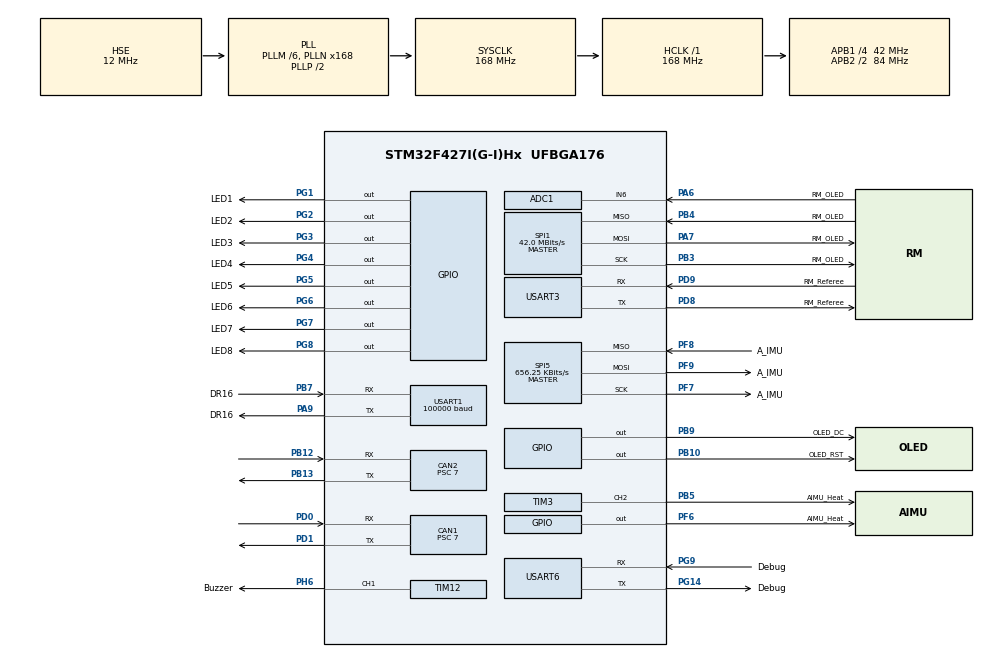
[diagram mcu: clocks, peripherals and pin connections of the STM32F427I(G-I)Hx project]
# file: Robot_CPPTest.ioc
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ADC1.Channel-0\#ChannelRegularConversion=ADC_CHANNEL_6
ADC1.NbrOfConversionFlag=1
ADC1.Rank-0\#ChannelRegularConversion=1
ADC1.SamplingTime-0\#ChannelRegularConversion=ADC_SAMPLETIME_15CYCLES
ADC1.master=1
CAN1.ABOM=ENABLE
CAN1.AWUM=ENABLE
CAN1.BS1=CAN_BS1_3TQ
CAN1.BS2=CAN_BS2_2TQ
CAN1.CalculateTimeQuantum=166.66666666666669
CAN1.NART=ENABLE
CAN1.Prescaler=7
CAN1.SJW=CAN_SJW_1TQ
CAN1.TXFP=ENABLE
CAN2.ABOM=ENABLE
CAN2.AWUM=ENABLE
CAN2.BS1=CAN_BS1_3TQ
CAN2.BS2=CAN_BS2_2TQ
CAN2.CalculateTimeQuantum=166.66666666666669
CAN2.NART=ENABLE
CAN2.Prescaler=7
CAN2.TXFP=ENABLE
Dma.Request0=USART1_RX
Dma.Request1=USART3_RX
Dma.Request2=USART3_TX
Dma.Request3=USART6_TX
Dma.USART1_RX.0.Direction=DMA_PERIPH_TO_MEMORY
Dma.USART1_RX.0.FIFOMode=DMA_FIFOMODE_DISABLE
Dma.USART1_RX.0.Instance=DMA2_Stream2
Dma.USART1_RX.0.MemDataAlignment=DMA_MDATAALIGN_BYTE
Dma.USART1_RX.0.MemInc=DMA_MINC_ENABLE
Dma.USART1_RX.0.Mode=DMA_CIRCULAR
Dma.USART1_RX.0.PeriphDataAlignment=DMA_PDATAALIGN_BYTE
Dma.USART1_RX.0.PeriphInc=DMA_PINC_DISABLE
Dma.USART1_RX.0.Priority=DMA_PRIORITY_LOW
Dma.USART3_RX.1.Direction=DMA_PERIPH_TO_MEMORY
Dma.USART3_RX.1.FIFOMode=DMA_FIFOMODE_DISABLE
Dma.USART3_RX.1.Instance=DMA1_Stream1
Dma.USART3_RX.1.MemDataAlignment=DMA_MDATAALIGN_BYTE
Dma.USART3_RX.1.MemInc=DMA_MINC_ENABLE
Dma.USART3_RX.1.Mode=DMA_CIRCULAR
Dma.USART3_RX.1.PeriphDataAlignment=DMA_PDATAALIGN_BYTE
Dma.USART3_RX.1.PeriphInc=DMA_PINC_DISABLE
Dma.USART3_RX.1.Priority=DMA_PRIORITY_LOW
Dma.USART3_TX.2.Direction=DMA_MEMORY_TO_PERIPH
Dma.USART3_TX.2.FIFOMode=DMA_FIFOMODE_DISABLE
Dma.USART3_TX.2.Instance=DMA1_Stream3
Dma.USART3_TX.2.MemDataAlignment=DMA_MDATAALIGN_BYTE
Dma.USART3_TX.2.MemInc=DMA_MINC_ENABLE
Dma.USART3_TX.2.Mode=DMA_NORMAL
Dma.USART3_TX.2.PeriphDataAlignment=DMA_PDATAALIGN_BYTE
Dma.USART3_TX.2.PeriphInc=DMA_PINC_DISABLE
Dma.USART3_TX.2.Priority=DMA_PRIORITY_LOW
Dma.USART6_TX.3.Direction=DMA_MEMORY_TO_PERIPH
Dma.USART6_TX.3.FIFOMode=DMA_FIFOMODE_DISABLE
Dma.USART6_TX.3.Instance=DMA2_Stream6
Dma.USART6_TX.3.MemDataAlignment=DMA_MDATAALIGN_BYTE
Dma.USART6_TX.3.MemInc=DMA_MINC_ENABLE
Dma.USART6_TX.3.Mode=DMA_NORMAL
Dma.USART6_TX.3.PeriphDataAlignment=DMA_PDATAALIGN_BYTE
Dma.USART6_TX.3.PeriphInc=DMA_PINC_DISABLE
Dma.USART6_TX.3.Priority=DMA_PRIORITY_LOW
FREERTOS.INCLUDE_vTaskDelayUntil=1
FREERTOS.Tasks01=Activate_Task,0,128,User_SystemInit_Task,Default,NULL,Dynamic,NULL,NULL
Mcu.Family=STM32F4
Mcu.Name=STM32F427I(G-I)Hx
Mcu.Package=UFBGA176
NVIC.CAN1_RX0_IRQn=true\:5\:0\:true\:false\:true\:false\:true\:true
NVIC.CAN2_RX0_IRQn=true\:5\:0\:true\:false\:true\:false\:true\:true
NVIC.DMA1_Stream1_IRQn=true\:5\:0\:true\:false\:true\:true\:false\:true
NVIC.DMA1_Stream3_IRQn=true\:5\:0\:true\:false\:true\:true\:false\:true
NVIC.DMA2_Stream2_IRQn=true\:0\:0\:false\:false\:true\:true\:false\:true
NVIC.DMA2_Stream6_IRQn=true\:5\:0\:true\:false\:true\:true\:false\:true
NVIC.PriorityGroup=NVIC_PRIORITYGROUP_4
NVIC.TIM6_DAC_IRQn=true\:0\:0\:false\:false\:true\:false\:false\:true
NVIC.TimeBase=TIM6_DAC_IRQn
NVIC.TimeBaseIP=TIM6
NVIC.USART1_IRQn=true\:5\:0\:true\:false\:true\:false\:true\:true
NVIC.USART3_IRQn=true\:5\:0\:true\:false\:true\:true\:true\:true
NVIC.USART6_IRQn=true\:5\:0\:true\:false\:true\:false\:true\:true
PA13.Mode=Serial_Wire
PA13.Signal=SYS_JTMS-SWDIO
PA14.Mode=Serial_Wire
PA14.Signal=SYS_JTCK-SWCLK
PA6.GPIO_Label=RM_OLED
PA6.Signal=ADCx_IN6
PA7.GPIO_Label=RM_OLED
PA7.Mode=Full_Duplex_Master
PA7.Signal=SPI1_MOSI
PA9.GPIO_Label=DR16
PA9.Mode=Asynchronous
PA9.Signal=USART1_TX
PB10.GPIO_Label=OLED_RST
PB10.Signal=GPIO_Output
PB12.Mode=Slave
PB12.Signal=CAN2_RX
PB13.Mode=Slave
PB13.Signal=CAN2_TX
PB3.GPIO_Label=RM_OLED
PB3.Mode=Full_Duplex_Master
PB3.Signal=SPI1_SCK
PB4.GPIO_Label=RM_OLED
PB4.Mode=Full_Duplex_Master
PB4.Signal=SPI1_MISO
PB5.GPIO_Label=AIMU_Heat
PB5.Signal=S_TIM3_CH2
PB7.GPIO_Label=DR16
PB7.Mode=Asynchronous
PB7.Signal=USART1_RX
PB9.GPIO_Label=OLED_DC
PB9.Signal=GPIO_Output
PD0.Mode=Master
PD0.Signal=CAN1_RX
PD1.Mode=Master
PD1.Signal=CAN1_TX
PD8.GPIO_Label=RM_Referee
PD8.Mode=Asynchronous
PD8.Signal=USART3_TX
PD9.GPIO_Label=RM_Referee
PD9.Mode=Asynchronous
PD9.Signal=USART3_RX
PF6.GPIO_Label=AIMU_Heat
PF6.PinState=GPIO_PIN_SET
PF6.Signal=GPIO_Output
PF7.GPIO_Label=A_IMU
PF7.Mode=Full_Duplex_Master
PF7.Signal=SPI5_SCK
PF8.GPIO_Label=A_IMU
PF8.Mode=Full_Duplex_Master
PF8.Signal=SPI5_MISO
PF9.GPIO_Label=A_IMU
PF9.Mode=Full_Duplex_Master
PF9.Signal=SPI5_MOSI
PG1.GPIO_Label=LED1
PG1.GPIO_PuPd=GPIO_PULLUP
PG1.PinState=GPIO_PIN_SET
PG1.Signal=GPIO_Output
PG14.GPIO_Label=Debug
PG14.Mode=Asynchronous
PG14.Signal=USART6_TX
PG2.GPIO_Label=LED2
PG2.GPIO_PuPd=GPIO_PULLUP
PG2.PinState=GPIO_PIN_SET
PG2.Signal=GPIO_Output
PG3.GPIO_Label=LED3
PG3.GPIO_PuPd=GPIO_PULLUP
PG3.PinState=GPIO_PIN_SET
PG3.Signal=GPIO_Output
PG4.GPIO_Label=LED4
PG4.GPIO_PuPd=GPIO_PULLUP
PG4.PinState=GPIO_PIN_SET
PG4.Signal=GPIO_Output
PG5.GPIO_Label=LED5
PG5.GPIO_PuPd=GPIO_PULLUP
PG5.PinState=GPIO_PIN_SET
PG5.Signal=GPIO_Output
PG6.GPIO_Label=LED6
PG6.GPIO_PuPd=GPIO_PULLUP
PG6.PinState=GPIO_PIN_SET
PG6.Signal=GPIO_Output
PG7.GPIO_Label=LED7
PG7.GPIO_ModeDefaultOutputPP=GPIO_MODE_OUTPUT_PP
PG7.GPIO_PuPd=GPIO_PULLUP
PG7.PinState=GPIO_PIN_SET
PG7.Signal=GPIO_Output
PG8.GPIO_Label=LED8
PG8.GPIO_PuPd=GPIO_PULLUP
PG8.PinState=GPIO_PIN_SET
PG8.Signal=GPIO_Output
PG9.GPIO_Label=Debug
PG9.Mode=Asynchronous
PG9.Signal=USART6_RX
PH0/OSC_IN.Mode=HSE-External-Oscillator
PH0/OSC_IN.Signal=RCC_OSC_IN
PH1/OSC_OUT.Mode=HSE-External-Oscillator
PH1/OSC_OUT.Signal=RCC_OSC_OUT
PH6.GPIO_Label=Buzzer
PH6.Signal=S_TIM12_CH1
ProjectManager.HeapSize=0x200
ProjectManager.StackSize=0x400
ProjectManager.TargetToolchain=MDK-ARM V5.27
RCC.48MHZClocksFreq_Value=84000000
RCC.AHBFreq_Value=168000000
RCC.APB1CLKDivider=RCC_HCLK_DIV4
RCC.APB1Freq_Value=42000000
RCC.APB1TimFreq_Value=84000000
RCC.APB2CLKDivider=RCC_HCLK_DIV2
RCC.APB2Freq_Value=84000000
RCC.APB2TimFreq_Value=168000000
RCC.CortexFreq_Value=168000000
RCC.HCLKFreq_Value=168000000
RCC.HSE_VALUE=12000000
RCC.HSI_VALUE=16000000
RCC.LSE_VALUE=32768
RCC.PLLM=6
RCC.PLLN=168
RCC.PLLSourceVirtual=RCC_PLLSOURCE_HSE
RCC.SYSCLKFreq_VALUE=168000000
RCC.SYSCLKSource=RCC_SYSCLKSOURCE_PLLCLK
RCC.VCOOutputFreq_Value=336000000
SH.ADCx_IN6.0=ADC1_IN6,IN6
SH.S_TIM12_CH1.0=TIM12_CH1,PWM Generation1 CH1
SH.S_TIM3_CH2.0=TIM3_CH2,PWM Generation2 CH2
SPI1.CalculateBaudRate=42.0 MBits/s
SPI1.Direction=SPI_DIRECTION_2LINES
SPI1.Mode=SPI_MODE_MASTER
SPI1.VirtualType=VM_MASTER
SPI5.BaudRatePrescaler=SPI_BAUDRATEPRESCALER_128
SPI5.CalculateBaudRate=656.25 KBits/s
SPI5.Direction=SPI_DIRECTION_2LINES
SPI5.Mode=SPI_MODE_MASTER
SPI5.VirtualType=VM_MASTER
TIM12.Channel-PWM\ Generation1\ CH1=TIM_CHANNEL_1
TIM12.Period=2499
TIM12.Prescaler=83
TIM12.Pulse-PWM\ Generation1\ CH1=1000
TIM3.Channel-PWM\ Generation2\ CH2=TIM_CHANNEL_2
TIM3.Period=4999
USART1.BaudRate=100000
USART1.Parity=PARITY_EVEN
USART1.VirtualMode=VM_ASYNC
USART1.WordLength=WORDLENGTH_9B
USART3.VirtualMode=VM_ASYNC
USART6.VirtualMode=VM_ASYNC
VP_FREERTOS_VS_CMSIS_V1.Mode=CMSIS_V1
VP_SYS_VS_tim6.Mode=TIM6
VP_TIM12_VS_ClockSourceINT.Mode=Internal
board=custom

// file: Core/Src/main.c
/* USER CODE BEGIN Header */
/**
  ******************************************************************************
  * @file           : main.c
  * @brief          : Main program body
  ******************************************************************************
  * @attention
  *
  * <h2><center>&copy; Copyright (c) 2021 STMicroelectronics.
  * All rights reserved.</center></h2>
  *
  * This software component is licensed by ST under Ultimate Liberty license
  * SLA0044, the "License"; You may not use this file except in compliance with
  * the License. You may obtain a copy of the License at:
  *                             www.st.com/SLA0044
  *
  ******************************************************************************
  */
/* USER CODE END Header */
#include "main.h"
#include "cmsis_os.h"
#include "adc.h"
#include "can.h"
#include "dma.h"
#include "spi.h"
#include "tim.h"
#include "usart.h"
#include "gpio.h"

/* USER CODE BEGIN Includes */
#include "System_Config.h"
#include "DJI_AIMU.h"//这里进行了修改test
#include "BSP_FLASH.h"
#include "BSP_FlashStore.h"
/* USER CODE END Includes */

void SystemClock_Config(void);
void MX_FREERTOS_Init(void);

int main(void)
{

  /* MCU Configuration--------------------------------------------------------*/

  HAL_Init();

  /* Configure the system clock */
  SystemClock_Config();

  /* Initialize all configured peripherals */
  MX_GPIO_Init();
  MX_DMA_Init();
  MX_CAN1_Init();
  MX_CAN2_Init();
  MX_USART1_UART_Init();
  MX_USART6_UART_Init();
  MX_SPI5_Init();
  MX_TIM3_Init();
  MX_USART3_UART_Init();
  MX_ADC1_Init();
  MX_SPI1_Init();
  MX_TIM12_Init();
  /* USER CODE BEGIN 2 */
#if AIMU_Calibrate == AIMU_Calibrate_Off
  flash_read(STM32_FLASH_BASE, IMU_Offset, 6);
#endif
  User_System_Init();

  /* USER CODE END 2 */

  /* Call init function for freertos objects (in freertos.c) */
  MX_FREERTOS_Init();
  /* Start scheduler */
  osKernelStart();

  /* We should never get here as control is now taken by the scheduler */
  /* Infinite loop */
  /* USER CODE BEGIN WHILE */
#if AIMU_Calibrate == AIMU_Calibrate_On
  flash_write_single_address(STM32_FLASH_BASE, IMUwriteFlashData, 6);
  // DJI_IMUWriteOffset(IMUwriteFlashData,6);
#endif
  while (1)
  {
    /* USER CODE END WHILE */

  }
}

void SystemClock_Config(void)
{
  RCC_OscInitTypeDef RCC_OscInitStruct = {0};
  RCC_ClkInitTypeDef RCC_ClkInitStruct = {0};

  /** Configure the main internal regulator output voltage
  */
  __HAL_RCC_PWR_CLK_ENABLE();
  __HAL_PWR_VOLTAGESCALING_CONFIG(PWR_REGULATOR_VOLTAGE_SCALE1);
  /** Initializes the RCC Oscillators according to the specified parameters
  * in the RCC_OscInitTypeDef structure.
  */
  RCC_OscInitStruct.OscillatorType = RCC_OSCILLATORTYPE_HSE;
  RCC_OscInitStruct.HSEState = RCC_HSE_ON;
  RCC_OscInitStruct.PLL.PLLState = RCC_PLL_ON;
  RCC_OscInitStruct.PLL.PLLSource = RCC_PLLSOURCE_HSE;
  RCC_OscInitStruct.PLL.PLLM = 6;
  RCC_OscInitStruct.PLL.PLLN = 168;
  RCC_OscInitStruct.PLL.PLLP = RCC_PLLP_DIV2;
  RCC_OscInitStruct.PLL.PLLQ = 4;
  if (HAL_RCC_OscConfig(&RCC_OscInitStruct) != HAL_OK)
  {
    Error_Handler();
  }
  /** Initializes the CPU, AHB and APB buses clocks
  */
  RCC_ClkInitStruct.ClockType = RCC_CLOCKTYPE_HCLK|RCC_CLOCKTYPE_SYSCLK
                              |RCC_CLOCKTYPE_PCLK1|RCC_CLOCKTYPE_PCLK2;
  RCC_ClkInitStruct.SYSCLKSource = RCC_SYSCLKSOURCE_PLLCLK;
  RCC_ClkInitStruct.AHBCLKDivider = RCC_SYSCLK_DIV1;
  RCC_ClkInitStruct.APB1CLKDivider = RCC_HCLK_DIV4;
  RCC_ClkInitStruct.APB2CLKDivider = RCC_HCLK_DIV2;

  if (HAL_RCC_ClockConfig(&RCC_ClkInitStruct, FLASH_LATENCY_5) != HAL_OK)
  {
    Error_Handler();
  }
}

void HAL_TIM_PeriodElapsedCallback(TIM_HandleTypeDef *htim)
{
  if (htim->Instance == TIM6) {
    HAL_IncTick();
  }
}

void Error_Handler(void)
{
}

/************************ (C) COPYRIGHT STMicroelectronics *****END OF FILE****/
